# FM33FK5XX register map
File version: 1.0
CPU: Cortex-M33 r1p0, little endian, MPU, FPU, 3 interrupt priority bits
Registers are 32-bit, read-write, reset 0x0 unless marked. A register's access mark holds for its fields unless they carry their own. Offsets are from the block's base; [hi:lo] are bit positions; {n}, {i} and the like mark numbered series.

## FLS — FLS module information
Base 0x40001000
0x00 RDCR — FlashReadControlRegister
  [2:0] FLS_WAIT — FLS_WAIT field description
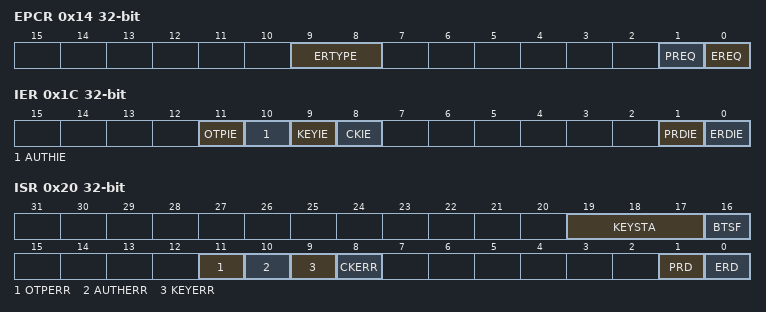
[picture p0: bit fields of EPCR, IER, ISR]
0x14 EPCR — FlashErase/ProgramControlRegister
  [9:8] ERTYPE — ERTYPE field description
  [1] PREQ — PREQ field description
  [0] EREQ — EREQ field description
0x18 KEY wo — FlashKeyRegister
  [31:0] KEY — KEY field description
0x1C IER — FlashInterruptEnableRegister
  [11] OTPIE — OTPIE field description
  [10] AUTHIE — AUTHIE field description
  [9] KEYIE — KEYIE field description
  [8] CKIE — CKIE field description
  [1] PRDIE — PRDIE field description
  [0] ERDIE — ERDIE field description
0x20 ISR access per field — FlashInterruptStatusRegister
  [19:17] KEYSTA ro — KEYSTA field description
  [16] BTSF ro — BTSF field description
  [11] OTPERR rw — OTPERR field description
  [10] AUTHERR rw — AUTHERR field description
  [9] KEYERR rw — KEYERR field description
  [8] CKERR rw — CKERR field description
  [1] PRD rw — PRD field description
  [0] ERD rw — ERD field description

## PMU — PMU module information
Base 0x40002000
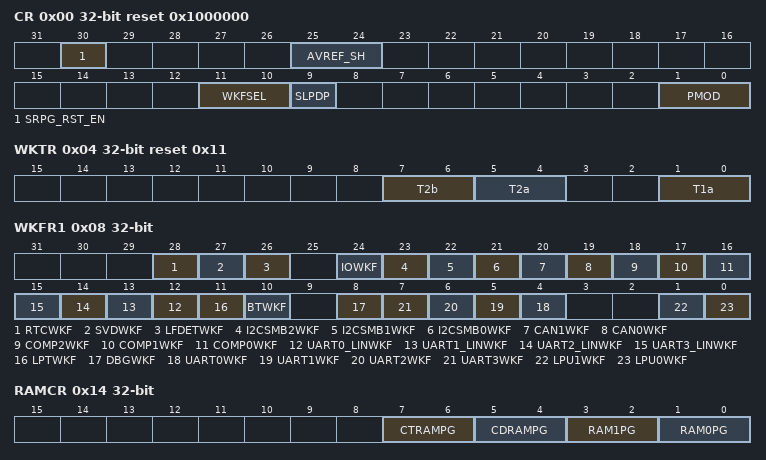
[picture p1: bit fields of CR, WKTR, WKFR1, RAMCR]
0x00 CR reset 0x1000000 — PowerManagementControlRegister
  [30] SRPG_RST_EN — SRPG_RST_EN field description
  [25:24] AVREF_SH — AVREF_SH field description
  [11:10] WKFSEL — WKFSEL field description
  [9] SLPDP — SLPDP field description
  [1:0] PMOD — PMOD field description
0x04 WKTR reset 0x11 — WakeupTimeRegister
  [7:6] T2b — T2b field description
  [5:4] T2a — T2a field description
  [1:0] T1a — T1a field description
0x08 WKFR1 access per field — WakeupSourceFlagsRegister1
  [28] RTCWKF ro — RTCWKF field description
  [27] SVDWKF ro — SVDWKF field description
  [26] LFDETWKF ro — LFDETWKF field description
  [24] IOWKF ro — IOWKF field description
  [23] I2CSMB2WKF ro — I2CSMB2WKF field description
  [22] I2CSMB1WKF ro — I2CSMB1WKF field description
  [21] I2CSMB0WKF ro — I2CSMB0WKF field description
  [20] CAN1WKF ro — CAN1WKF field description
  [19] CAN0WKF ro — CAN0WKF field description
  [18] COMP2WKF ro — COMP2WKF field description
  [17] COMP1WKF ro — COMP1WKF field description
  [16] COMP0WKF ro — COMP0WKF field description
  [n+12] UART{n}_LINWKF ro (n=0..3) — UART{n}_LINWKF field description
  [11] LPTWKF ro — LPTWKF field description
  [10] BTWKF ro — BTWKF field description
  [8] DBGWKF rw — DBGWKF field description
  [n+4] UART{n}WKF ro (n=0..3) — UART{n}WKF field description
  [1] LPU1WKF ro — LPU1WKF field description
  [0] LPU0WKF ro — LPU0WKF field description
0x0C WKFR2 — WakeupSourceFlagsRegister2
  [7:0] WKPxF — WKPxF field description
0x14 RAMCR
  [7:6] CTRAMPG — CTRAMPG field description
  [5:4] CDRAMPG — CDRAMPG field description
  [3:2] RAM1PG — RAM1PG field description
  [1:0] RAM0PG — RAM0PG field description
0x38 ULPBG_CR reset 0x10
  [4:0] ULPBG_TRIM — ULPBG_TRIM field description
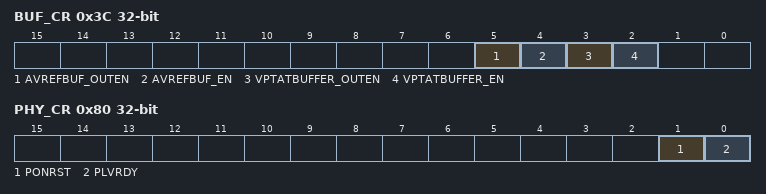
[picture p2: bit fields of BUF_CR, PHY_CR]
0x3C BUF_CR — PMUAnalogBufferControlRegister
  [5] AVREFBUF_OUTEN — AVREFBUF_OUTEN field description
  [4] AVREFBUF_EN — AVREFBUF_EN field description
  [3] VPTATBUFFER_OUTEN — VPTATBUFFER_OUTEN field description
  [2] VPTATBUFFER_EN — VPTATBUFFER_EN field description
0x44 VREFP_CFGR — PMUVREFPConfigRegister
  [1:0] VRS — VRS field description
0x4C VREFP_TR reset 0x80 — PMUVREFPTrimRegister
  [7:0] TRIM — TRIM field description
0x50 PTAT_CR — PMUPTATControlRegister
  [0] PTAT_EN — PTAT_EN field description
0x54 AUXEN reset 0x1
  [1:0] AUXEN — AUXEN field description
0x80 PHY_CR
  [1] PONRST — PONRST field description
  [0] PLVRDY — PLVRDY field description

## VAO — VAO module information
Base 0x4001F800
0x00 RSTCR — VBATResetControlRegister
  [0] VBAT_RST — VBAT_RST field description
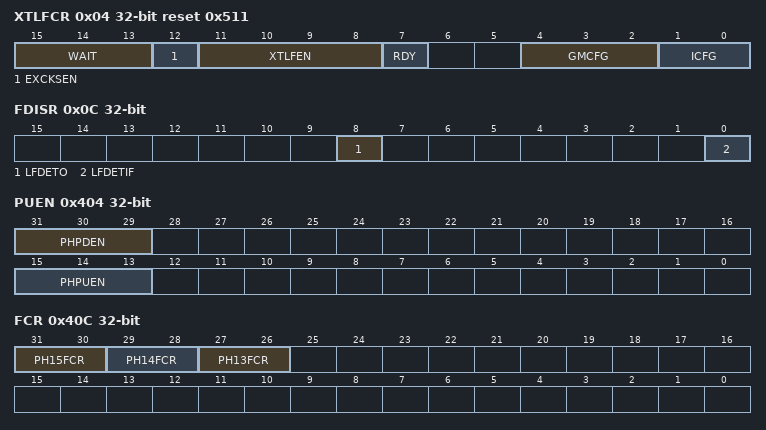
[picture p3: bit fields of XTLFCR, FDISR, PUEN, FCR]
0x04 XTLFCR access per field reset 0x511 — XTLFControlRegister
  [15:13] WAIT rw — WAIT field description
  [12] EXCKSEN rw — EXCKSEN field description
  [11:8] XTLFEN rw — XTLFEN field description
  [7] RDY ro — RDY field description
  [4:2] GMCFG rw — GMCFG field description
  [1:0] ICFG rw — ICFG field description
0x08 FDIER — XTLFOscillationFailDetectionInterruptEnableRegister
  [0] LFDET_IE — LFDET_IE field description
0x0C FDISR access per field — XTLFOscillationFailDetectionInterruptStatusRegister
  [8] LFDETO ro — LFDETO field description
  [0] LFDETIF rw — LFDETIF field description
0x400 INEN — VAOIOInputEnableRegister
  [15:13] PHINEN — PHINEN field description
0x404 PUEN — VAOIOPull-upEnableRegister
  [31:29] PHPDEN — PHPDEN field description
  [15:13] PHPUEN — PHPUEN field description
0x408 ODEN — VAOIOOpenDrainEnableRegister
  [15:13] PHODEN — PHODEN field description
0x40C FCR — VAOIOFunctionControlRegister
  [31:30] PH15FCR — PH15FCR field description
  [29:28] PH14FCR — PH14FCR field description
  [27:26] PH13FCR — PH13FCR field description
0x410 DOR — VAOIODataOutputRegister
  [15:13] PHDO — PHDO field description
0x414 DIR — VAOIODataInputRegister
  [15:13] PHDIN — PHDIN field description
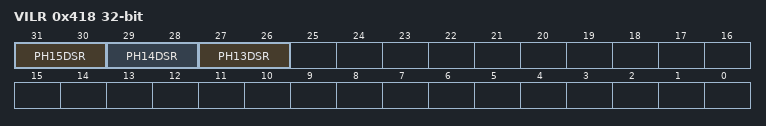
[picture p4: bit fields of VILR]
0x418 VILR — VAOIOVoltageInputLowRegister
  [31:30] PH15DSR — PH15DSR field description
  [29:28] PH14DSR — PH14DSR field description
  [27:26] PH13DSR — PH13DSR field description
